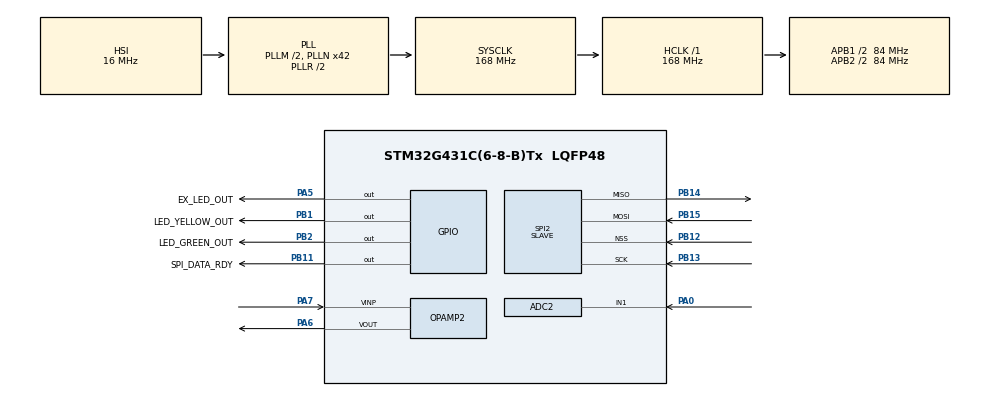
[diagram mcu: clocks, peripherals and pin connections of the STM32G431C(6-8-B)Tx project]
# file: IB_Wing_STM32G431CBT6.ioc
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ADC1.Channel-0\#ChannelRegularConversion=ADC_CHANNEL_VREFINT
ADC1.NbrOfConversionFlag=1
ADC1.OffsetNumber-0\#ChannelRegularConversion=ADC_OFFSET_NONE
ADC1.Rank-0\#ChannelRegularConversion=1
ADC1.SamplingTime-0\#ChannelRegularConversion=ADC_SAMPLETIME_2CYCLES_5
ADC1.master=1
ADC2.Channel-0\#ChannelRegularConversion=ADC_CHANNEL_1
ADC2.DMAContinuousRequests=ENABLE
ADC2.ExternalTrigConv=ADC_EXTERNALTRIG_T6_TRGO
ADC2.NbrOfConversionFlag=1
ADC2.OffsetNumber-0\#ChannelRegularConversion=ADC_OFFSET_NONE
ADC2.Rank-0\#ChannelRegularConversion=1
ADC2.SamplingTime-0\#ChannelRegularConversion=ADC_SAMPLETIME_2CYCLES_5
Dma.ADC2.0.Direction=DMA_PERIPH_TO_MEMORY
Dma.ADC2.0.EventEnable=DISABLE
Dma.ADC2.0.Instance=DMA1_Channel2
Dma.ADC2.0.MemDataAlignment=DMA_MDATAALIGN_HALFWORD
Dma.ADC2.0.MemInc=DMA_MINC_ENABLE
Dma.ADC2.0.Mode=DMA_CIRCULAR
Dma.ADC2.0.PeriphDataAlignment=DMA_PDATAALIGN_HALFWORD
Dma.ADC2.0.PeriphInc=DMA_PINC_DISABLE
Dma.ADC2.0.Polarity=HAL_DMAMUX_REQ_GEN_RISING
Dma.ADC2.0.Priority=DMA_PRIORITY_HIGH
Dma.ADC2.0.RequestNumber=1
Dma.ADC2.0.SignalID=NONE
Dma.ADC2.0.SyncEnable=DISABLE
Dma.ADC2.0.SyncPolarity=HAL_DMAMUX_SYNC_NO_EVENT
Dma.ADC2.0.SyncRequestNumber=1
Dma.ADC2.0.SyncSignalID=NONE
Dma.Request0=ADC2
Dma.Request1=SPI2_TX
Dma.SPI2_TX.1.Direction=DMA_MEMORY_TO_PERIPH
Dma.SPI2_TX.1.EventEnable=DISABLE
Dma.SPI2_TX.1.Instance=DMA2_Channel2
Dma.SPI2_TX.1.MemDataAlignment=DMA_MDATAALIGN_BYTE
Dma.SPI2_TX.1.MemInc=DMA_MINC_ENABLE
Dma.SPI2_TX.1.Mode=DMA_NORMAL
Dma.SPI2_TX.1.PeriphDataAlignment=DMA_PDATAALIGN_BYTE
Dma.SPI2_TX.1.PeriphInc=DMA_PINC_DISABLE
Dma.SPI2_TX.1.Polarity=HAL_DMAMUX_REQ_GEN_RISING
Dma.SPI2_TX.1.Priority=DMA_PRIORITY_HIGH
Dma.SPI2_TX.1.RequestNumber=1
Dma.SPI2_TX.1.SignalID=NONE
Dma.SPI2_TX.1.SyncEnable=DISABLE
Dma.SPI2_TX.1.SyncPolarity=HAL_DMAMUX_SYNC_NO_EVENT
Dma.SPI2_TX.1.SyncRequestNumber=1
Dma.SPI2_TX.1.SyncSignalID=NONE
Mcu.Family=STM32G4
Mcu.Name=STM32G431C(6-8-B)Tx
Mcu.Package=LQFP48
NVIC.ADC1_2_IRQn=true\:0\:0\:false\:false\:true\:true\:true\:true
NVIC.DMA1_Channel2_IRQn=true\:0\:0\:false\:false\:true\:false\:true\:true
NVIC.DMA2_Channel2_IRQn=true\:0\:0\:false\:false\:true\:false\:true\:true
NVIC.PriorityGroup=NVIC_PRIORITYGROUP_4
NVIC.SPI2_IRQn=true\:0\:0\:false\:false\:true\:true\:true\:true
NVIC.TIM6_DAC_IRQn=true\:0\:0\:false\:false\:true\:true\:true\:true
PA0.Mode=IN1-Single-Ended
PA0.Signal=ADC2_IN1
PA5.GPIO_Label=EX_LED_OUT
PA5.Signal=GPIO_Output
PA6.Mode=Follower
PA6.Signal=OPAMP2_VOUT
PA7.Mode=Follower
PA7.Signal=OPAMP2_VINP
PB1.GPIO_Label=LED_YELLOW_OUT
PB1.Signal=GPIO_Output
PB11.GPIO_Label=SPI_DATA_RDY
PB11.GPIO_PuPd=GPIO_PULLDOWN
PB11.GPIO_Speed=GPIO_SPEED_FREQ_MEDIUM
PB11.Signal=GPIO_Output
PB12.Mode=NSS_Signal_Hard_Input
PB12.Signal=SPI2_NSS
PB13.Mode=Full_Duplex_Slave
PB13.Signal=SPI2_SCK
PB14.Mode=Full_Duplex_Slave
PB14.Signal=SPI2_MISO
PB15.Mode=Full_Duplex_Slave
PB15.Signal=SPI2_MOSI
PB2.GPIO_Label=LED_GREEN_OUT
PB2.Signal=GPIO_Output
ProjectManager.HeapSize=0x200
ProjectManager.StackSize=0x400
ProjectManager.TargetToolchain=CMake
RCC.ADC12Freq_Value=168000000
RCC.AHBFreq_Value=168000000
RCC.APB1CLKDivider=RCC_HCLK_DIV2
RCC.APB1Freq_Value=84000000
RCC.APB1TimFreq_Value=168000000
RCC.APB2CLKDivider=RCC_HCLK_DIV2
RCC.APB2Freq_Value=84000000
RCC.APB2TimFreq_Value=168000000
RCC.CortexFreq_Value=168000000
RCC.EXTERNAL_CLOCK_VALUE=12288000
RCC.HCLKFreq_Value=168000000
RCC.HSE_VALUE=8000000
RCC.HSI48_VALUE=48000000
RCC.HSI_VALUE=16000000
RCC.LSE_VALUE=32768
RCC.PLLM=RCC_PLLM_DIV2
RCC.PLLN=42
RCC.SYSCLKFreq_VALUE=168000000
RCC.SYSCLKSource=RCC_SYSCLKSOURCE_PLLCLK
RCC.USBFreq_Value=168000000
RCC.VCOOutputFreq_Value=336000000
SPI2.DataSize=SPI_DATASIZE_8BIT
SPI2.Direction=SPI_DIRECTION_2LINES
SPI2.Mode=SPI_MODE_SLAVE
SPI2.VirtualNSS=VM_NSSHARD
SPI2.VirtualType=VM_SLAVE
TIM6.PeriodNoDither=1679
TIM6.TIM_MasterOutputTrigger=TIM_TRGO_UPDATE
VP_ADC1_Vref_Input.Mode=IN-Vrefint
VP_SYS_VS_DBSignals.Mode=DisableDeadBatterySignals
VP_TIM6_VS_ClockSourceINT.Mode=Enable_Timer
board=custom

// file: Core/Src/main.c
/* USER CODE BEGIN Header */
/**
 ******************************************************************************
 * @file           : main.c
 * @brief          : Main program body
 ******************************************************************************
 * @attention
 *
 * Copyright (c) 2025 STMicroelectronics.
 * All rights reserved.
 *
 * This software is licensed under terms that can be found in the LICENSE file
 * in the root directory of this software component.
 * If no LICENSE file comes with this software, it is provided AS-IS.
 *
 ******************************************************************************
 */
/* USER CODE END Header */
#include "main.h"

/* USER CODE BEGIN Includes */
#include "app.h"
#include "hal_cfg.h"
#include "prj_config.h"
#include "solution_wrapper.h"
/* USER CODE END Includes */

ADC_HandleTypeDef hadc1;
ADC_HandleTypeDef hadc2;
DMA_HandleTypeDef hdma_adc2;

OPAMP_HandleTypeDef hopamp2;

SPI_HandleTypeDef hspi2;
DMA_HandleTypeDef hdma_spi2_tx;

TIM_HandleTypeDef htim6;

void SystemClock_Config(void);
static void MX_GPIO_Init(void);
static void MX_DMA_Init(void);
static void MX_ADC1_Init(void);
static void MX_ADC2_Init(void);
static void MX_OPAMP2_Init(void);
static void MX_SPI2_Init(void);
static void MX_TIM6_Init(void);

int main(void) {

    /* MCU Configuration--------------------------------------------------------*/

    /* Reset of all peripherals, Initializes the Flash interface and the Systick. */
    HAL_Init();

    /* Configure the system clock */
    SystemClock_Config();

    /* USER CODE BEGIN SysInit */
#if START_UP_DELAY_ENABLE
    /* Provide delay before initialization to settle up power */
    HAL_Delay(100);
#endif
    /* USER CODE END SysInit */

    /* Initialize all configured peripherals */
    MX_GPIO_Init();
    MX_DMA_Init();
    MX_ADC1_Init();
    MX_ADC2_Init();
    MX_OPAMP2_Init();
#if (SPI_LOGGER_ENABLE == 1u)
    MX_SPI2_Init(); /* Logger SPI2 slave - only needed when logger is enabled */
#endif
    MX_TIM6_Init();
    /* USER CODE BEGIN 2 */
    /* Configure Solution HAL peripherals */
    Solution_HalConfigure();
    /* Init Solution HAL layer */
    Solution_HalInit();

    /* Init application layer */
    App_InitRun();
    /* USER CODE END 2 */

    /* Infinite loop */
    /* USER CODE BEGIN WHILE */
    while (1) {
        App_Task();

        /* USER CODE END WHILE */

    }
}

void SystemClock_Config(void) {
    RCC_OscInitTypeDef RCC_OscInitStruct = {0};
    RCC_ClkInitTypeDef RCC_ClkInitStruct = {0};

    /** Configure the main internal regulator output voltage
     */
    HAL_PWREx_ControlVoltageScaling(PWR_REGULATOR_VOLTAGE_SCALE1_BOOST);

    /** Initializes the RCC Oscillators according to the specified parameters
     * in the RCC_OscInitTypeDef structure.
     */
    RCC_OscInitStruct.OscillatorType = RCC_OSCILLATORTYPE_HSI;
    RCC_OscInitStruct.HSIState = RCC_HSI_ON;
    RCC_OscInitStruct.HSICalibrationValue = RCC_HSICALIBRATION_DEFAULT;
    RCC_OscInitStruct.PLL.PLLState = RCC_PLL_ON;
    RCC_OscInitStruct.PLL.PLLSource = RCC_PLLSOURCE_HSI;
    RCC_OscInitStruct.PLL.PLLM = RCC_PLLM_DIV2;
    RCC_OscInitStruct.PLL.PLLN = 42;
    RCC_OscInitStruct.PLL.PLLP = RCC_PLLP_DIV2;
    RCC_OscInitStruct.PLL.PLLQ = RCC_PLLQ_DIV2;
    RCC_OscInitStruct.PLL.PLLR = RCC_PLLR_DIV2;
    if (HAL_RCC_OscConfig(&RCC_OscInitStruct) != HAL_OK) {
        Error_Handler();
    }

    /** Initializes the CPU, AHB and APB buses clocks
     */
    RCC_ClkInitStruct.ClockType = RCC_CLOCKTYPE_HCLK | RCC_CLOCKTYPE_SYSCLK | RCC_CLOCKTYPE_PCLK1 | RCC_CLOCKTYPE_PCLK2;
    RCC_ClkInitStruct.SYSCLKSource = RCC_SYSCLKSOURCE_PLLCLK;
    RCC_ClkInitStruct.AHBCLKDivider = RCC_SYSCLK_DIV1;
    RCC_ClkInitStruct.APB1CLKDivider = RCC_HCLK_DIV2;
    RCC_ClkInitStruct.APB2CLKDivider = RCC_HCLK_DIV2;

    if (HAL_RCC_ClockConfig(&RCC_ClkInitStruct, FLASH_LATENCY_4) != HAL_OK) {
        Error_Handler();
    }
}

static void MX_ADC1_Init(void) {

    ADC_MultiModeTypeDef multimode = {0};
    ADC_ChannelConfTypeDef sConfig = {0};

    /** Common config
     */
    hadc1.Instance = ADC1;
    hadc1.Init.ClockPrescaler = ADC_CLOCK_SYNC_PCLK_DIV4;
    hadc1.Init.Resolution = ADC_RESOLUTION_12B;
    hadc1.Init.DataAlign = ADC_DATAALIGN_RIGHT;
    hadc1.Init.GainCompensation = 0;
    hadc1.Init.ScanConvMode = ADC_SCAN_DISABLE;
    hadc1.Init.EOCSelection = ADC_EOC_SINGLE_CONV;
    hadc1.Init.LowPowerAutoWait = DISABLE;
    hadc1.Init.ContinuousConvMode = DISABLE;
    hadc1.Init.NbrOfConversion = 1;
    hadc1.Init.DiscontinuousConvMode = DISABLE;
    hadc1.Init.ExternalTrigConv = ADC_SOFTWARE_START;
    hadc1.Init.ExternalTrigConvEdge = ADC_EXTERNALTRIGCONVEDGE_NONE;
    hadc1.Init.DMAContinuousRequests = DISABLE;
    hadc1.Init.Overrun = ADC_OVR_DATA_PRESERVED;
    hadc1.Init.OversamplingMode = DISABLE;
    if (HAL_ADC_Init(&hadc1) != HAL_OK) {
        Error_Handler();
    }

    /** Configure the ADC multi-mode
     */
    multimode.Mode = ADC_MODE_INDEPENDENT;
    if (HAL_ADCEx_MultiModeConfigChannel(&hadc1, &multimode) != HAL_OK) {
        Error_Handler();
    }

    /** Configure Regular Channel
     */
    sConfig.Channel = ADC_CHANNEL_VREFINT;
    sConfig.Rank = ADC_REGULAR_RANK_1;
    sConfig.SamplingTime = ADC_SAMPLETIME_2CYCLES_5;
    sConfig.SingleDiff = ADC_SINGLE_ENDED;
    sConfig.OffsetNumber = ADC_OFFSET_NONE;
    sConfig.Offset = 0;
    if (HAL_ADC_ConfigChannel(&hadc1, &sConfig) != HAL_OK) {
        Error_Handler();
    }
}

static void MX_ADC2_Init(void) {

    ADC_ChannelConfTypeDef sConfig = {0};

    /** Common config
     */
    hadc2.Instance = ADC2;
    hadc2.Init.ClockPrescaler = ADC_CLOCK_SYNC_PCLK_DIV4;
    hadc2.Init.Resolution = ADC_RESOLUTION_12B;
    hadc2.Init.DataAlign = ADC_DATAALIGN_RIGHT;
    hadc2.Init.GainCompensation = 0;
    hadc2.Init.ScanConvMode = ADC_SCAN_DISABLE;
    hadc2.Init.EOCSelection = ADC_EOC_SINGLE_CONV;
    hadc2.Init.LowPowerAutoWait = DISABLE;
    hadc2.Init.ContinuousConvMode = DISABLE;
    hadc2.Init.NbrOfConversion = 1;
    hadc2.Init.DiscontinuousConvMode = DISABLE;
    hadc2.Init.ExternalTrigConv = ADC_EXTERNALTRIG_T6_TRGO;
    hadc2.Init.ExternalTrigConvEdge = ADC_EXTERNALTRIGCONVEDGE_RISING;
    hadc2.Init.DMAContinuousRequests = ENABLE;
    hadc2.Init.Overrun = ADC_OVR_DATA_PRESERVED;
    hadc2.Init.OversamplingMode = DISABLE;
    if (HAL_ADC_Init(&hadc2) != HAL_OK) {
        Error_Handler();
    }

    /** Configure Regular Channel
     */
    sConfig.Channel = ADC_CHANNEL_1;
    sConfig.Rank = ADC_REGULAR_RANK_1;
    sConfig.SamplingTime = ADC_SAMPLETIME_2CYCLES_5;
    sConfig.SingleDiff = ADC_SINGLE_ENDED;
    sConfig.OffsetNumber = ADC_OFFSET_NONE;
    sConfig.Offset = 0;
    if (HAL_ADC_ConfigChannel(&hadc2, &sConfig) != HAL_OK) {
        Error_Handler();
    }
}

static void MX_OPAMP2_Init(void) {

    hopamp2.Instance = OPAMP2;
    hopamp2.Init.PowerMode = OPAMP_POWERMODE_NORMALSPEED;
    hopamp2.Init.Mode = OPAMP_FOLLOWER_MODE;
    hopamp2.Init.NonInvertingInput = OPAMP_NONINVERTINGINPUT_IO0;
    hopamp2.Init.InternalOutput = DISABLE;
    hopamp2.Init.TimerControlledMuxmode = OPAMP_TIMERCONTROLLEDMUXMODE_DISABLE;
    hopamp2.Init.UserTrimming = OPAMP_TRIMMING_FACTORY;
    if (HAL_OPAMP_Init(&hopamp2) != HAL_OK) {
        Error_Handler();
    }
}

static void MX_SPI2_Init(void) {

    /* SPI2 parameter configuration*/
    hspi2.Instance = SPI2;
    hspi2.Init.Mode = SPI_MODE_SLAVE;
    hspi2.Init.Direction = SPI_DIRECTION_2LINES;
    hspi2.Init.DataSize = SPI_DATASIZE_8BIT;
    hspi2.Init.CLKPolarity = SPI_POLARITY_LOW;
    hspi2.Init.CLKPhase = SPI_PHASE_1EDGE;
    hspi2.Init.NSS = SPI_NSS_HARD_INPUT;
    hspi2.Init.FirstBit = SPI_FIRSTBIT_MSB;
    hspi2.Init.TIMode = SPI_TIMODE_DISABLE;
    hspi2.Init.CRCCalculation = SPI_CRCCALCULATION_DISABLE;
    hspi2.Init.CRCPolynomial = 7;
    hspi2.Init.CRCLength = SPI_CRC_LENGTH_DATASIZE;
    hspi2.Init.NSSPMode = SPI_NSS_PULSE_DISABLE;
    if (HAL_SPI_Init(&hspi2) != HAL_OK) {
        Error_Handler();
    }
}

static void MX_TIM6_Init(void) {

    TIM_MasterConfigTypeDef sMasterConfig = {0};

    htim6.Instance = TIM6;
    htim6.Init.Prescaler = 0;
    htim6.Init.CounterMode = TIM_COUNTERMODE_UP;
    htim6.Init.Period = 1679;
    htim6.Init.AutoReloadPreload = TIM_AUTORELOAD_PRELOAD_DISABLE;
    if (HAL_TIM_Base_Init(&htim6) != HAL_OK) {
        Error_Handler();
    }
    sMasterConfig.MasterOutputTrigger = TIM_TRGO_UPDATE;
    sMasterConfig.MasterSlaveMode = TIM_MASTERSLAVEMODE_DISABLE;
    if (HAL_TIMEx_MasterConfigSynchronization(&htim6, &sMasterConfig) != HAL_OK) {
        Error_Handler();
    }
}

static void MX_DMA_Init(void) {
    /* DMA controller clock enable */
    __HAL_RCC_DMAMUX1_CLK_ENABLE();
    __HAL_RCC_DMA1_CLK_ENABLE();
    __HAL_RCC_DMA2_CLK_ENABLE();

    /* DMA interrupt init */
    /* DMA1_Channel2_IRQn interrupt configuration */
    HAL_NVIC_SetPriority(DMA1_Channel2_IRQn, 0, 0);
    HAL_NVIC_EnableIRQ(DMA1_Channel2_IRQn);
    /* DMA2_Channel2_IRQn interrupt configuration */
    HAL_NVIC_SetPriority(DMA2_Channel2_IRQn, 0, 0);
    HAL_NVIC_EnableIRQ(DMA2_Channel2_IRQn);
}

static void MX_GPIO_Init(void) {
    GPIO_InitTypeDef GPIO_InitStruct = {0};

    /* GPIO Ports Clock Enable */
    __HAL_RCC_GPIOA_CLK_ENABLE();
    __HAL_RCC_GPIOB_CLK_ENABLE();

    /*Configure GPIO pin Output Level */
    HAL_GPIO_WritePin(EX_LED_OUT_GPIO_Port, EX_LED_OUT_Pin, GPIO_PIN_RESET);

    /*Configure GPIO pin Output Level */
    HAL_GPIO_WritePin(GPIOB, LED_YELLOW_OUT_Pin | LED_GREEN_OUT_Pin | SPI_DATA_RDY_Pin, GPIO_PIN_RESET);

    /*Configure GPIO pin : EX_LED_OUT_Pin */
    GPIO_InitStruct.Pin = EX_LED_OUT_Pin;
    GPIO_InitStruct.Mode = GPIO_MODE_OUTPUT_PP;
    GPIO_InitStruct.Pull = GPIO_NOPULL;
    GPIO_InitStruct.Speed = GPIO_SPEED_FREQ_LOW;
    HAL_GPIO_Init(EX_LED_OUT_GPIO_Port, &GPIO_InitStruct);

    /*Configure GPIO pins : LED_YELLOW_OUT_Pin LED_GREEN_OUT_Pin */
    GPIO_InitStruct.Pin = LED_YELLOW_OUT_Pin | LED_GREEN_OUT_Pin;
    GPIO_InitStruct.Mode = GPIO_MODE_OUTPUT_PP;
    GPIO_InitStruct.Pull = GPIO_NOPULL;
    GPIO_InitStruct.Speed = GPIO_SPEED_FREQ_LOW;
    HAL_GPIO_Init(GPIOB, &GPIO_InitStruct);

    /*Configure GPIO pin : SPI_DATA_RDY_Pin */
    GPIO_InitStruct.Pin = SPI_DATA_RDY_Pin;
    GPIO_InitStruct.Mode = GPIO_MODE_OUTPUT_PP;
    GPIO_InitStruct.Pull = GPIO_PULLDOWN;
    GPIO_InitStruct.Speed = GPIO_SPEED_FREQ_MEDIUM;
    HAL_GPIO_Init(SPI_DATA_RDY_GPIO_Port, &GPIO_InitStruct);

}

void Error_Handler(void) {
    __disable_irq();
    while (1) {}
}
